# RK3399-AP register map
File version: 1
CPU: CA7 r0p1, little endian, MPU, FPU, I-cache, D-cache, VTOR, 4 interrupt priority bits, 32 interrupts
Registers are 32-bit, read-write, reset 0x0 unless marked. A register's access mark holds for its fields unless they carry their own. Offsets are from the block's base; [hi:lo] are bit positions; {n}, {i} and the like mark numbered series.

## DMAC0
Base 0xFF6D0000
Same registers: DMAC1 0xFF6E0000
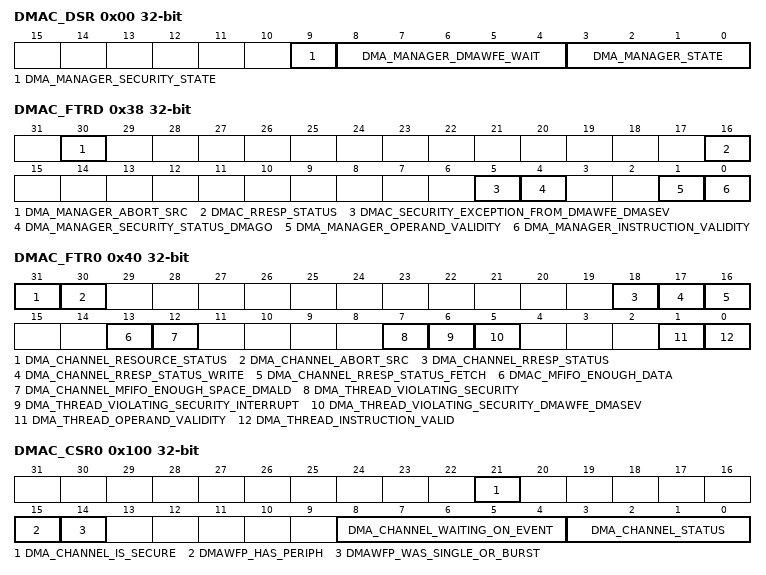
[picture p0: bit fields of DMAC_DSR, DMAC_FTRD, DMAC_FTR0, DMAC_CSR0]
0x00 DMAC_DSR ro — DMA Manager Status Register
  [9] DMA_MANAGER_SECURITY_STATE — Provides the security status of the DMA manager thread: 0 = DMA manager operates in the Secure state 1 = DMA manager operates in the Non-secure state.
  [8:4] DMA_MANAGER_DMAWFE_WAIT — When the DMA manager thread executes a DMAWFE instruction, it waits for the following event to occur: b00000 = event[0] b00001 = event[1] b00010 = event[2] … b11111 = event[31].
  [3:0] DMA_MANAGER_STATE — The operating state of the DMA manager: b0000 = Stopped b0001 = Executing b0010 = Cache miss b0011 = Updating PC b0100 = Waiting for event b0101-b1110 = reserved b1111 = Faulting.
0x04 DMAC_DPC ro — DMA Program Counter Register
  [31:0] DMAC_DPC — Program counter for the DMA manager thread
0x20 DMAC_INTEN — Interrupt Enable Register
  [31:0] DMAC_INTEN — Program the appropriate bit to control how the DMAC responds
0x24 DMAC_EVENT_RIS ro — Event-Interrupt Raw Status Register
  [31:0] DMAC_EVENT_RIS — Returns the status of the event-interrupt resources:
0x28 DMAC_INTMIS ro — Interrupt Status Register
  [31:0] DMAC_INTMIS — Provides the status of the interrupts that are active in the DMAC:
0x2C DMAC_INTCLR wo — Interrupt Clear Register
  [31:0] DMAC_INTCLR — Controls the clearing of the irq outputs:
0x30 DMAC_FSRD ro — Fault Status DMA Manager Register
  [31:0] DMAC_FSRD — Provides the fault status of the DMA manager. Read as:
0x34 DMAC_FSRC ro — Fault Status DMA Channel Register
  [31:0] DMAC_FSRC — Each bit provides the fault status of the corresponding channel.
0x38 DMAC_FTRD access per field — Fault Type DMA Manager Register
  [30] DMA_MANAGER_ABORT_SRC ro — If the DMA manager aborts, this bit indicates if the erroneous instruction was read from the system memory or from the debug interface: 0 = instruction that generated an abort was read from system memory 1 = instruction that generated an abort was read from the debug interface.
  [16] DMAC_RRESP_STATUS ro — Indicates the AXI response that the DMAC receives on the RRESP bus, after the DMA manager performs an instruction fetch: 0 = OKAY response 1 = EXOKAY, SLVERR, or DECERR response
  [5] DMAC_SECURITY_EXCEPTION_FROM_DMAWFE_DMASEV ro — Indicates if the DMA manager was attempting to execute DMAWFE or DMASEV with inappropriate security permissions: 0 = DMA manager has appropriate security to execute DMAWFE or DMASEV 1 = a DMA manager thread in the Non-secure state attempted to execute either: DMAWFE to wait for a secure event DMASEV to create a secure event or secure interrupt
  [4] DMA_MANAGER_SECURITY_STATUS_DMAGO ro — Indicates if the DMA manager was attempting to execute DMAGO with inappropriate security permissions: 0 = DMA manager has appropriate security to execute DMAGO 1 = DMA manager thread in the Non-secure state attempted to execute DMAGO to create a DMA channel operating in the Secure state.
  [1] DMA_MANAGER_OPERAND_VALIDITY ro — Indicates if the DMA manager was attempting to execute an instruction operand that was not valid for the configuration of the DMAC: 0 = valid operand 1 = invalid operand.
  [0] DMA_MANAGER_INSTRUCTION_VALIDITY rw — Indicates if the DMA manager was attempting to execute an undefined instruction: 0 = defined instruction 1 = undefined instruction.
0x40 DMAC_FTR0 ro — Fault Type DMA Channel Register
  [31] DMA_CHANNEL_RESOURCE_STATUS — Indicates if the DMA channel has locked-up because of resource starvation: 0 = DMA channel has adequate resources 1 = DMA channel has locked-up because of insufficient resources. This fault is an imprecise abort
  [30] DMA_CHANNEL_ABORT_SRC — If the DMA channel aborts, this bit indicates if the erroneous instruction was read from the system memory or from the debug interface: 0 = instruction that generated an abort was read from system memory 1 = instruction that generated an abort was read from the debug interface. This fault is an imprecise abort but the bit is only valid when a precise abort occurs.
  [18] DMA_CHANNEL_RRESP_STATUS — Indicates the AXI response that the DMAC receives on the RRESP bus, after the DMA channel thread performs a data read: 0 = OKAY response 1 = EXOKAY, SLVERR, or DECERR response. This fault is an imprecise abort
  [17] DMA_CHANNEL_RRESP_STATUS_WRITE — Indicates the AXI response that the DMAC receives on the BRESP bus, after the DMA channel thread performs a data write: 0 = OKAY response 1 = EXOKAY, SLVERR, or DECERR response. This fault is an imprecise abort.
  [16] DMA_CHANNEL_RRESP_STATUS_FETCH — Indicates the AXI response that the DMAC receives on the RRESP bus, after the DMA channel thread performs an instruction fetch: 0 = OKAY response 1 = EXOKAY, SLVERR, or DECERR response. This fault is a precise abort.
  [13] DMAC_MFIFO_ENOUGH_DATA — Indicates if the MFIFO did not contain the data to enable the DMAC to perform the DMAST: 0 = MFIFO contains all the data to enable the DMAST to complete 1 = previous DMALDs have not put enough data in the MFIFO to enable the DMAST to complete. This fault is a precise abort.
  [12] DMA_CHANNEL_MFIFO_ENOUGH_SPACE_DMALD — Indicates if the MFIFO prevented the DMA channel thread from executing DMALD or DMAST. Depending on the instruction: DMALD 0 = MFIFO contains sufficient space 1 = MFIFO is too small to hold the data that DMALD requires. DMAST 0 = MFIFO contains sufficient data 1 = MFIFO is too small to store the data to enable DMAST to complete. This fault is an imprecise abort
  [7] DMA_THREAD_VIOLATING_SECURITY — Indicates if a DMA channel thread, in the Non-secure state, attempts to program the CCRn Register to perform a secure read or secure write: 0 = a DMA channel thread in the Non-secure state is not violating the security permissions 1 = a DMA channel thread in the Non-secure state attempted to perform a secure read or secure write. This fault is a precise abort
  [6] DMA_THREAD_VIOLATING_SECURITY_INTERRUPT — Indicates if a DMA channel thread, in the Non-secure state, attempts to execute DMAWFP, DMALDP, DMASTP, or DMAFLUSHP with inappropriate security permissions: 0 = a DMA channel thread in the Non-secure state is not violating the security permissions 1 = a DMA channel thread in the Non-secure state attempted to execute either: o DMAWFP to wait for a secure peripheral o DMALDP or DMASTP to notify a secure peripheral o DMAFLUSHP to flush a secure peripheral. This fault is a precise abort.
  [5] DMA_THREAD_VIOLATING_SECURITY_DMAWFE_DMASEV — Indicates if the DMA channel thread attempts to execute DMAWFE or DMASEV with inappropriate security permissions: 0 = a DMA channel thread in the Non-secure state is not violating the security permissions 1 = a DMA channel thread in the Non-secure state attempted to execute either: DMAWFE to wait for a secure event DMASEV to create a secure event or secure interrupt. This fault is a precise abort.
  [1] DMA_THREAD_OPERAND_VALIDITY — Indicates if the DMA channel thread was attempting to execute an instruction operand that was not valid for the configuration of the DMAC: 0 = valid operand 1 = invalid operand. This fault is a precise abort.
  [0] DMA_THREAD_INSTRUCTION_VALID — Indicates if the DMA channel thread was attempting to execute an undefined instruction: 0 = defined instruction 1 = undefined instruction. This fault is a precise abort
{0x40+4i} DMAC_FTR{i} access not given (i=1..7) — Fault Type DMA Channel Register
0x100 DMAC_CSR0 ro — Channel Status Registers
  [21] DMA_CHANNEL_IS_SECURE — The channel non-secure bit provides the security of the DMA channel: 0 = DMA channel operates in the Secure state 1 = DMA channel operates in the Non-secure state
  [15] DMAWFP_HAS_PERIPH — When the DMA channel thread executes DMAWFP this bit indicates if the periph operand was set: 0 = DMAWFP executed with the periph operand not set 1 = DMAWFP executed with the periph operand set
  [14] DMAWFP_WAS_SINGLE_OR_BURST — When the DMA channel thread executes DMAWFP this bit indicates if the burst or single operand were set: 0 = DMAWFP executed with the single operand set 1 = DMAWFP executed with the burst operand set.
  [8:4] DMA_CHANNEL_WAITING_ON_EVENT — If the DMA channel is in the Waiting for event state or the Waiting for peripheral state then these bits indicate the event or peripheral number that the channel is waiting for: b00000 = DMA channel is waiting for event, or peripheral, 0 b00001 = DMA channel is waiting for event, or peripheral, 1 b00010 = DMA channel is waiting for event, or peripheral, 2 … b11111 = DMA channel is waiting for event, or peripheral, 31
  [3:0] DMA_CHANNEL_STATUS — The channel status encoding is: b0000 = Stopped b0001 = Executing b0010 = Cache miss b0011 = Updating PC b0100 = Waiting for event b0101 = At barrier b0110 = reserved b0111 = Waiting for peripheral b1000 = Killing b1001 = Completing b1010-b1101 = reserved b1110 = Faulting completing b1111 = Faulting
0x104 DMAC_CPC0 ro — Channel Program Counter Registers
  [31:0] DMAC_CPC0 — Program counter for the DMA channel 0 thread
{0x100+8i} DMAC_CSR{i} access not given (i=1..7) — Channel Status Registers
{0x104+8i} DMAC_CPC{i} access not given (i=1..7) — Channel Program Counter Registers
0x400 DMAC_SAR0 ro — Source Address Registers
  [31:0] DMAC_SAR0 — Address of the source data for DMA channel 0
0x404 DMAC_DAR0 ro — Destination Address Registers/DestinationAddress Registers
  [31:0] DMAC_DAR0 — Address of the Destination data for DMA channel 0
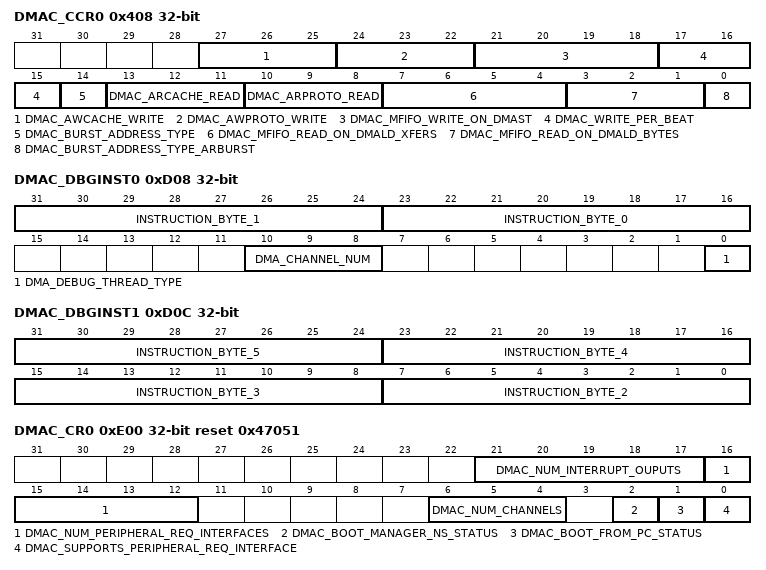
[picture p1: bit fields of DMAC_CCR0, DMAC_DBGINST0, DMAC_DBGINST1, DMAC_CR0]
0x408 DMAC_CCR0 ro — Channel Control Registers
  [27:25] DMAC_AWCACHE_WRITE — Programs the state of AWCACHE[3,1:0]a when the DMAC writes the destination data. Bit [27] 0 = AWCACHE[3] is LOW 1 = AWCACHE[3] is HIGH. Bit [26] 0 = AWCACHE[1] is LOW 1 = AWCACHE[1] is HIGH. Bit [25] 0 = AWCACHE[0] is LOW 1 = AWCACHE[0] is HIGH
  [24:22] DMAC_AWPROTO_WRITE — Programs the state of AWPROT[2:0]a when the DMAC writes the destination data. Bit [24] 0 = AWPROT[2] is LOW 1 = AWPROT[2] is HIGH. Bit [23] 0 = AWPROT[1] is LOW 1 = AWPROT[1] is HIGH. Bit [22] 0 = AWPROT[0] is LOW 1 = AWPROT[0] is HIGH
  [21:18] DMAC_MFIFO_WRITE_ON_DMAST — For each burst, these bits program the number of data transfers that the DMAC performs when it writes the destination data: b0000 = 1 data transfer b0001 = 2 data transfers b0010 = 3 data transfers … b1111 = 16 data transfers. The total number of bytes that the DMAC writes out of the MFIFO when it executes a DMAST instruction is the product of dst_burst_len and dst_burst_size
  [17:15] DMAC_WRITE_PER_BEAT — For each beat within a burst, it programs the number of bytes that the DMAC writes to the destination: b000 = writes 1 byte per beat b001 = writes 2 bytes per beat b010 = writes 4 bytes per beat b011 = writes 8 bytes per beat b100 = writes 16 bytes per beat b101-b111 = reserved. The total number of bytes that the DMAC writes out of the MFIFO when it executes a DMAST instruction is the product of dst_burst_len and dst_burst_size.
  [14] DMAC_BURST_ADDRESS_TYPE — Programs the burst type that the DMAC performs when it writes the destination data: 0 = Fixed-address burst. The DMAC signals AWBURST[0] LOW. 1 = Incrementing-address burst. The DMAC signals AWBURST[0] HIGH.
  [13:11] DMAC_ARCACHE_READ — Set the bits to control the state of ARCACHE[2:0]a when the DMAC reads the source data. Bit [13] 0 = ARCACHE[2] is LOW 1 = ARCACHE[2] is HIGH. Bit [12] 0 = ARCACHE[1] is LOW 1 = ARCACHE[1] is HIGH. Bit [11] 0 = ARCACHE[0] is LOW 1 = ARCACHE[0] is HIGH.
  [10:8] DMAC_ARPROTO_READ — Programs the state of ARPROT[2:0]a when the DMAC reads the source data. Bit [10] 0 = ARPROT[2] is LOW 1 = ARPROT[2] is HIGH. Bit [9] 0 = ARPROT[1] is LOW 1 = ARPROT[1] is HIGH. Bit [8] 0 = ARPROT[0] is LOW 1 = ARPROT[0] is HIGH.
  [7:4] DMAC_MFIFO_READ_ON_DMALD_XFERS — For each burst, these bits program the number of data transfers that the DMAC performs when it reads the source data: b0000 = 1 data transfer b0001 = 2 data transfers b0010 = 3 data transfers … b1111 = 16 data transfers. The total number of bytes that the DMAC reads into the MFIFO when it executes a DMALD instruction is the product of src_burst_len and src_burst_size
  [3:1] DMAC_MFIFO_READ_ON_DMALD_BYTES — For each beat within a burst, it programs the number of bytes that the DMAC reads from the source: b000 = reads 1 byte per beat b001 = reads 2 bytes per beat b010 = reads 4 bytes per beat b011 = reads 8 bytes per beat b100 = reads 16 bytes per beat b101-b111 = reserved. The total number of bytes that the DMAC reads into the MFIFO when it executes a DMALD instruction is the product of src_burst_len and src_burst_size
  [0] DMAC_BURST_ADDRESS_TYPE_ARBURST — Programs the burst type that the DMAC performs when it reads the source data: 0 = Fixed-address burst. The DMAC signals ARBURST[0] LOW. 1 = Incrementing-address burst. The DMAC signals ARBURST[0] HIGH
0x40C DMAC_LC0_0 ro — Loop Counter 0 Registers
  [7:0] LOOP_COUNTER_0 — Loop counter 0 iterations
0x410 DMAC_LC1_0 ro — Loop Counter 1 Registers
  [7:0] LOOP_COUNTER_1 — Loop counter 1 iterations
{0x400+0x20*i} DMAC_SAR{i} access not given (i=1..7) — Source Address Registers
{0x404+0x20*i} DMAC_DAR{i} access not given (i=1..7) — Destination Address Registers
{0x408+0x20*i} DMAC_CCR{i} access not given (i=1..7) — Channel Control Registers
{0x40C+0x20*i} DMAC_LC0_{i} access not given (i=1..7) — Loop Counter 0 Registers
{0x410+0x20*i} DMAC_LC1_{i} access not given (i=1..7) — Loop Counter 1 Registers
0xD00 DMAC_DBGSTATUS ro — Debug Status Register
  [1:0] EXECUTE_DBGINST — The debug encoding is as follows: b00 = execute the instruction that the DBGINST [1:0] Registers contain b01 = reserved b10 = reserved b11 = reserved.
0xD04 DMAC_DBGCMD wo — Debug Command Register
  [1:0] DEBUG_DBGINST2 — The debug encoding is as follows: b00 = execute the instruction that the DBGINST [1:0] Registers contain b01 = reserved b10 = reserved b11 = reserved
0xD08 DMAC_DBGINST0 wo — Debug Instruction-0 Register
  [31:24] INSTRUCTION_BYTE_1
  [23:16] INSTRUCTION_BYTE_0
  [10:8] DMA_CHANNEL_NUM — DMA channel number: b000 = DMA channel 0 b001 = DMA channel 1 b010 = DMA channel 2 … b111 = DMA channel 7
  [0] DMA_DEBUG_THREAD_TYPE — The debug thread encoding is as follows: 0 = DMA manager thread 1 = DMA channel.
0xD0C DMAC_DBGINST1 wo — Debug Instruction-1 Register
  [8n-9:8n-16] INSTRUCTION_BYTE_{n} (n=2..5)
0xE00 DMAC_CR0 ro reset 0x47051 — Configuration Register 0
  [21:17] DMAC_NUM_INTERRUPT_OUPUTS — Number of interrupt outputs that the DMAC provides: b00000 = 1 interrupt output, irq[0] b00001 = 2 interrupt outputs, irq[1:0] b00010 = 3 interrupt outputs, irq[2:0] … b11111 = 32 interrupt outputs, irq[31:0].
  [16:12] DMAC_NUM_PERIPHERAL_REQ_INTERFACES — Number of peripheral request interfaces that the DMAC provides: b00000 = 1 peripheral request interface b00001 = 2 peripheral request interfaces b00010 = 3 peripheral request interfaces … b11111 = 32 peripheral request interfaces.
  [6:4] DMAC_NUM_CHANNELS — Number of DMA channels that the DMAC supports: b000 = 1 DMA channel b001 = 2 DMA channels b010 = 3 DMA channels … b111 = 8 DMA channels.
  [2] DMAC_BOOT_MANAGER_NS_STATUS — Indicates the status of the boot_manager_ns signal when the DMAC exited from reset: 0 = boot_manager_ns was LOW 1 = boot_manager_ns was HIGH.
  [1] DMAC_BOOT_FROM_PC_STATUS — Indicates the status of the boot_from_pc signal when the DMAC exited from reset: 0 = boot_from_pc was LOW 1 = boot_from_pc was HIGH
  [0] DMAC_SUPPORTS_PERIPHERAL_REQ_INTERFACE — Supports peripheral requests: 0 = the DMAC does not provide a peripheral request interface 1 = the DMAC provides the number of peripheral request interfaces that the num_periph_req field specifies.
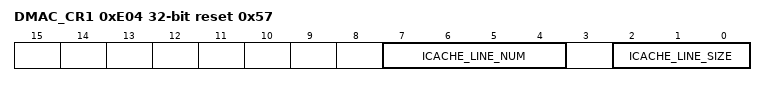
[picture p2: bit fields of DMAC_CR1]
0xE04 DMAC_CR1 ro reset 0x57 — Configuration Register 1
  [7:4] ICACHE_LINE_NUM — [7:4] num_i-cache_lines Number of i-cache lines: b0000 = 1 i-cache line b0001 = 2 i-cache lines b0010 = 3 i-cache lines … b1111 = 16 i-cache lines.
  [2:0] ICACHE_LINE_SIZE — The length of an i-cache line: b000-b001 = reserved b010 = 4 bytes b011 = 8 bytes b100 = 16 bytes b101 = 32 bytes b110-b111 = reserved
0xE08 DMAC_CR2 ro — Configuration Register 2
  [31:0] DMAC_CR2 — Provides the value of boot_addr[31:0] when the DMAC exited from
0xE0C DMAC_CR3 ro — Configuration Register 3
  [31:0] DMAC_CR3 — Provides the security state of an event-interrupt resource:
0xE10 DMAC_CR4 ro reset 0x6 — Configuration Register 4
  [31:0] DMAC_CR4 — Provides the security state of the peripheral request interfaces:
0xE14 DMAC_CRDn access not given reset 0x2094733 — DMA Configuration Register
0xE80 DMAC_WD — DMA Watchdog Register
  [0] DMAC_LOCKUP_ACTION — Controls how the DMAC responds when it detects a lock-up condition: 0 = the DMAC aborts all of the contributing DMA channels and sets irq_abort HIGH 1 = the DMAC sets irq_abort HIGH.
